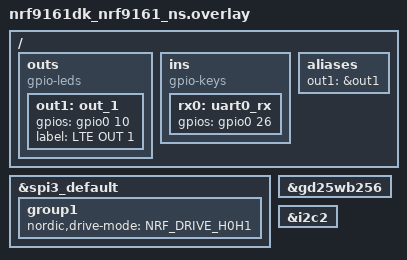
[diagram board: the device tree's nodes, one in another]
/*
 * Copyright (c) 2024 Achim Kraus CloudCoap.net
 *
 * See the NOTICE file(s) distributed with this work for additional
 * information regarding copyright ownership.
 *
 * This program and the accompanying materials are made available under the
 * terms of the Eclipse Public License 2.0 which is available at
 * http://www.eclipse.org/legal/epl-2.0
 *
 * SPDX-License-Identifier: EPL-2.0
 */

/*
 * Add outputs for LTE states "RRC connected" "LTE ready"
 * (ready := connected, PDN active, registered). 
 */ 

/	{

	outs {
		compatible = "gpio-leds";
		status = "okay";
		out1: out_1 {
			gpios = <&gpio0 10 0>;
			label = "LTE OUT 1";
		};

		/*		
		out2: out_2 {
			gpios = <&gpio0 20 0>;
			label = "LTE OUT 2";
		};
		*/  
	};

	ins {
		compatible = "gpio-keys";
		rx0: uart0_rx {
			gpios = <&gpio0 26 0>;
		};
	};

	aliases {
		out1 = &out1;
	/*  out2 = &out2; */

//		appl-storage-flash = &gd25wb256;
	};

};

&spi3_default {
	group1 {
		nordic,drive-mode = <NRF_DRIVE_H0H1>;
	};
};

&gd25wb256 {
//	status = "okay";
};

sensor_i2c: &i2c2 {};
